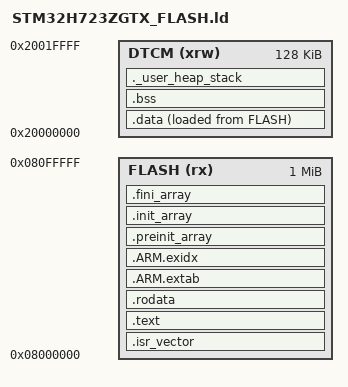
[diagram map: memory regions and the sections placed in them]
/* Linker script for STM32H723ZG: code in flash, data/bss/stack in DTCM. */

ENTRY(Reset_Handler)

MEMORY
{
  FLASH  (rx)  : ORIGIN = 0x08000000, LENGTH = 1024K
  DTCM   (xrw) : ORIGIN = 0x20000000, LENGTH = 128K
}

_estack = ORIGIN(DTCM) + LENGTH(DTCM);  /* stack grows down from the top of DTCM */
_Min_Stack_Size = 0x1000;               /* only used for the overflow check below */

SECTIONS
{
  .isr_vector :
  {
    . = ALIGN(4);
    KEEP(*(.isr_vector))
    . = ALIGN(4);
  } >FLASH

  .text :
  {
    . = ALIGN(4);
    *(.text)
    *(.text*)
    *(.glue_7)
    *(.glue_7t)
    *(.eh_frame)
    KEEP(*(.init))
    KEEP(*(.fini))
    . = ALIGN(4);
    _etext = .;
  } >FLASH

  .rodata :
  {
    . = ALIGN(4);
    *(.rodata)
    *(.rodata*)
    . = ALIGN(4);
  } >FLASH

  .ARM.extab : { *(.ARM.extab* .gnu.linkonce.armextab.*) } >FLASH
  .ARM.exidx :
  {
    __exidx_start = .;
    *(.ARM.exidx* .gnu.linkonce.armexidx.*)
    __exidx_end = .;
  } >FLASH

  /* Constructor/destructor tables walked by __libc_init_array in the startup code */
  .preinit_array :
  {
    PROVIDE_HIDDEN(__preinit_array_start = .);
    KEEP(*(.preinit_array*))
    PROVIDE_HIDDEN(__preinit_array_end = .);
  } >FLASH
  .init_array :
  {
    PROVIDE_HIDDEN(__init_array_start = .);
    KEEP(*(SORT(.init_array.*)))
    KEEP(*(.init_array*))
    PROVIDE_HIDDEN(__init_array_end = .);
  } >FLASH
  .fini_array :
  {
    PROVIDE_HIDDEN(__fini_array_start = .);
    KEEP(*(SORT(.fini_array.*)))
    KEEP(*(.fini_array*))
    PROVIDE_HIDDEN(__fini_array_end = .);
  } >FLASH

  /* Initialised data: lives in DTCM, initial values stored in flash and copied at reset */
  _sidata = LOADADDR(.data);
  .data :
  {
    . = ALIGN(4);
    _sdata = .;
    *(.data)
    *(.data*)
    . = ALIGN(4);
    _edata = .;
  } >DTCM AT> FLASH

  .bss (NOLOAD) :
  {
    . = ALIGN(4);
    _sbss = .;
    __bss_start__ = _sbss;
    *(.bss)
    *(.bss*)
    *(COMMON)
    . = ALIGN(4);
    _ebss = .;
    __bss_end__ = _ebss;
  } >DTCM

  /* Heap starts here (newlib's _sbrk uses 'end'); fail the link if the stack would not fit */
  ._user_heap_stack (NOLOAD) :
  {
    . = ALIGN(8);
    PROVIDE(end = .);
    PROVIDE(_end = .);
    . = . + _Min_Stack_Size;
    . = ALIGN(8);
  } >DTCM

  .ARM.attributes 0 : { *(.ARM.attributes) }
}
